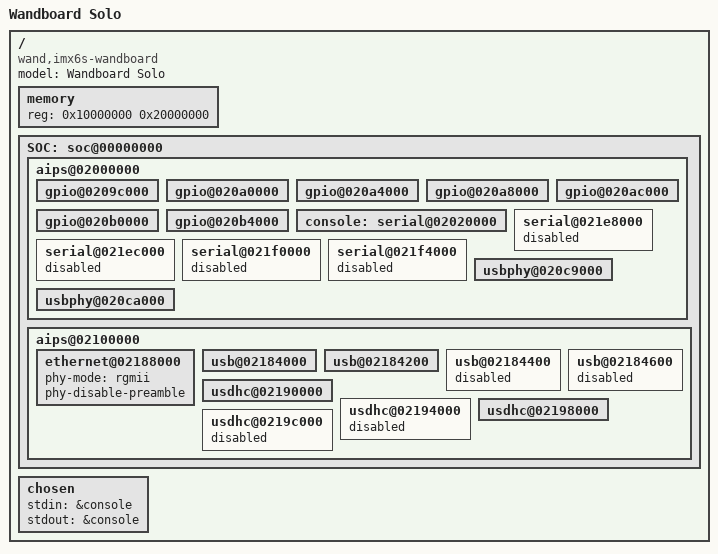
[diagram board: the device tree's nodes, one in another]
/*
 * Copyright (c) 2013 Ian Lepore
 * All rights reserved.
 *
 * Redistribution and use in source and binary forms, with or without
 * modification, are permitted provided that the following conditions
 * are met:
 * 1. Redistributions of source code must retain the above copyright
 *    notice, this list of conditions and the following disclaimer.
 * 2. Redistributions in binary form must reproduce the above copyright
 *    notice, this list of conditions and the following disclaimer in the
 *    documentation and/or other materials provided with the distribution.
 *
 * THIS SOFTWARE IS PROVIDED BY THE AUTHOR AND CONTRIBUTORS ``AS IS'' AND
 * ANY EXPRESS OR IMPLIED WARRANTIES, INCLUDING, BUT NOT LIMITED TO, THE
 * IMPLIED WARRANTIES OF MERCHANTABILITY AND FITNESS FOR A PARTICULAR PURPOSE
 * ARE DISCLAIMED. IN NO EVENT SHALL THE AUTHOR OR CONTRIBUTORS BE LIABLE
 * FOR ANY DIRECT, INDIRECT, INCIDENTAL, SPECIAL, EXEMPLARY, OR CONSEQUENTIAL
 * DAMAGES (INCLUDING, BUT NOT LIMITED TO, PROCUREMENT OF SUBSTITUTE GOODS
 * OR SERVICES; LOSS OF USE, DATA, OR PROFITS; OR BUSINESS INTERRUPTION)
 * HOWEVER CAUSED AND ON ANY THEORY OF LIABILITY, WHETHER IN CONTRACT, STRICT
 * LIABILITY, OR TORT (INCLUDING NEGLIGENCE OR OTHERWISE) ARISING IN ANY WAY
 * OUT OF THE USE OF THIS SOFTWARE, EVEN IF ADVISED OF THE POSSIBILITY OF
 * SUCH DAMAGE.
 *
 * Wandboard Solo.
 *
 * $FreeBSD$
 */

/dts-v1/;
/include/ "imx6.dtsi"

/ {
	#address-cells = <1>;
	#size-cells = <1>;

	model = "Wandboard Solo";
	compatible = "wand,imx6s-wandboard", "fsl,imx6s";

	memory {
		reg = <0x10000000 0x20000000>; /* RAM 512M */
	};

	SOC: soc@00000000 {
		aips@02000000 { /* AIPS1 */
			gpio@0209c000		{ status = "okay"; };
			gpio@020a0000		{ status = "okay"; };
			gpio@020a4000		{ status = "okay"; };
			gpio@020a8000		{ status = "okay"; };
			gpio@020ac000		{ status = "okay"; };
			gpio@020b0000		{ status = "okay"; };
			gpio@020b4000		{ status = "okay"; };
			console:serial@02020000 { status = "okay"; };
			serial@021e8000		{ status = "disabled"; };
			serial@021ec000		{ status = "disabled"; };
			serial@021f0000		{ status = "disabled"; };
			serial@021f4000		{ status = "disabled"; };
			usbphy@020c9000		{ status = "okay"; };
			usbphy@020ca000		{ status = "okay"; };
		};
		aips@02100000 { /* AIPS2 */
			ethernet@02188000	{
				status = "okay";
				phy-mode = "rgmii";
				phy-disable-preamble;
			};
			usb@02184000		{ status = "okay"; };
			usb@02184200		{ status = "okay"; };
			usb@02184400		{ status = "disabled"; };
			usb@02184600		{ status = "disabled"; };
			usdhc@02190000		{ status = "okay"; };
			usdhc@02194000		{ status = "disabled"; };
			usdhc@02198000		{ status = "okay"; };
			usdhc@0219c000		{ status = "disabled"; };
		};
	};

	chosen {
		stdin = &console;
		stdout = &console;
	};
};
